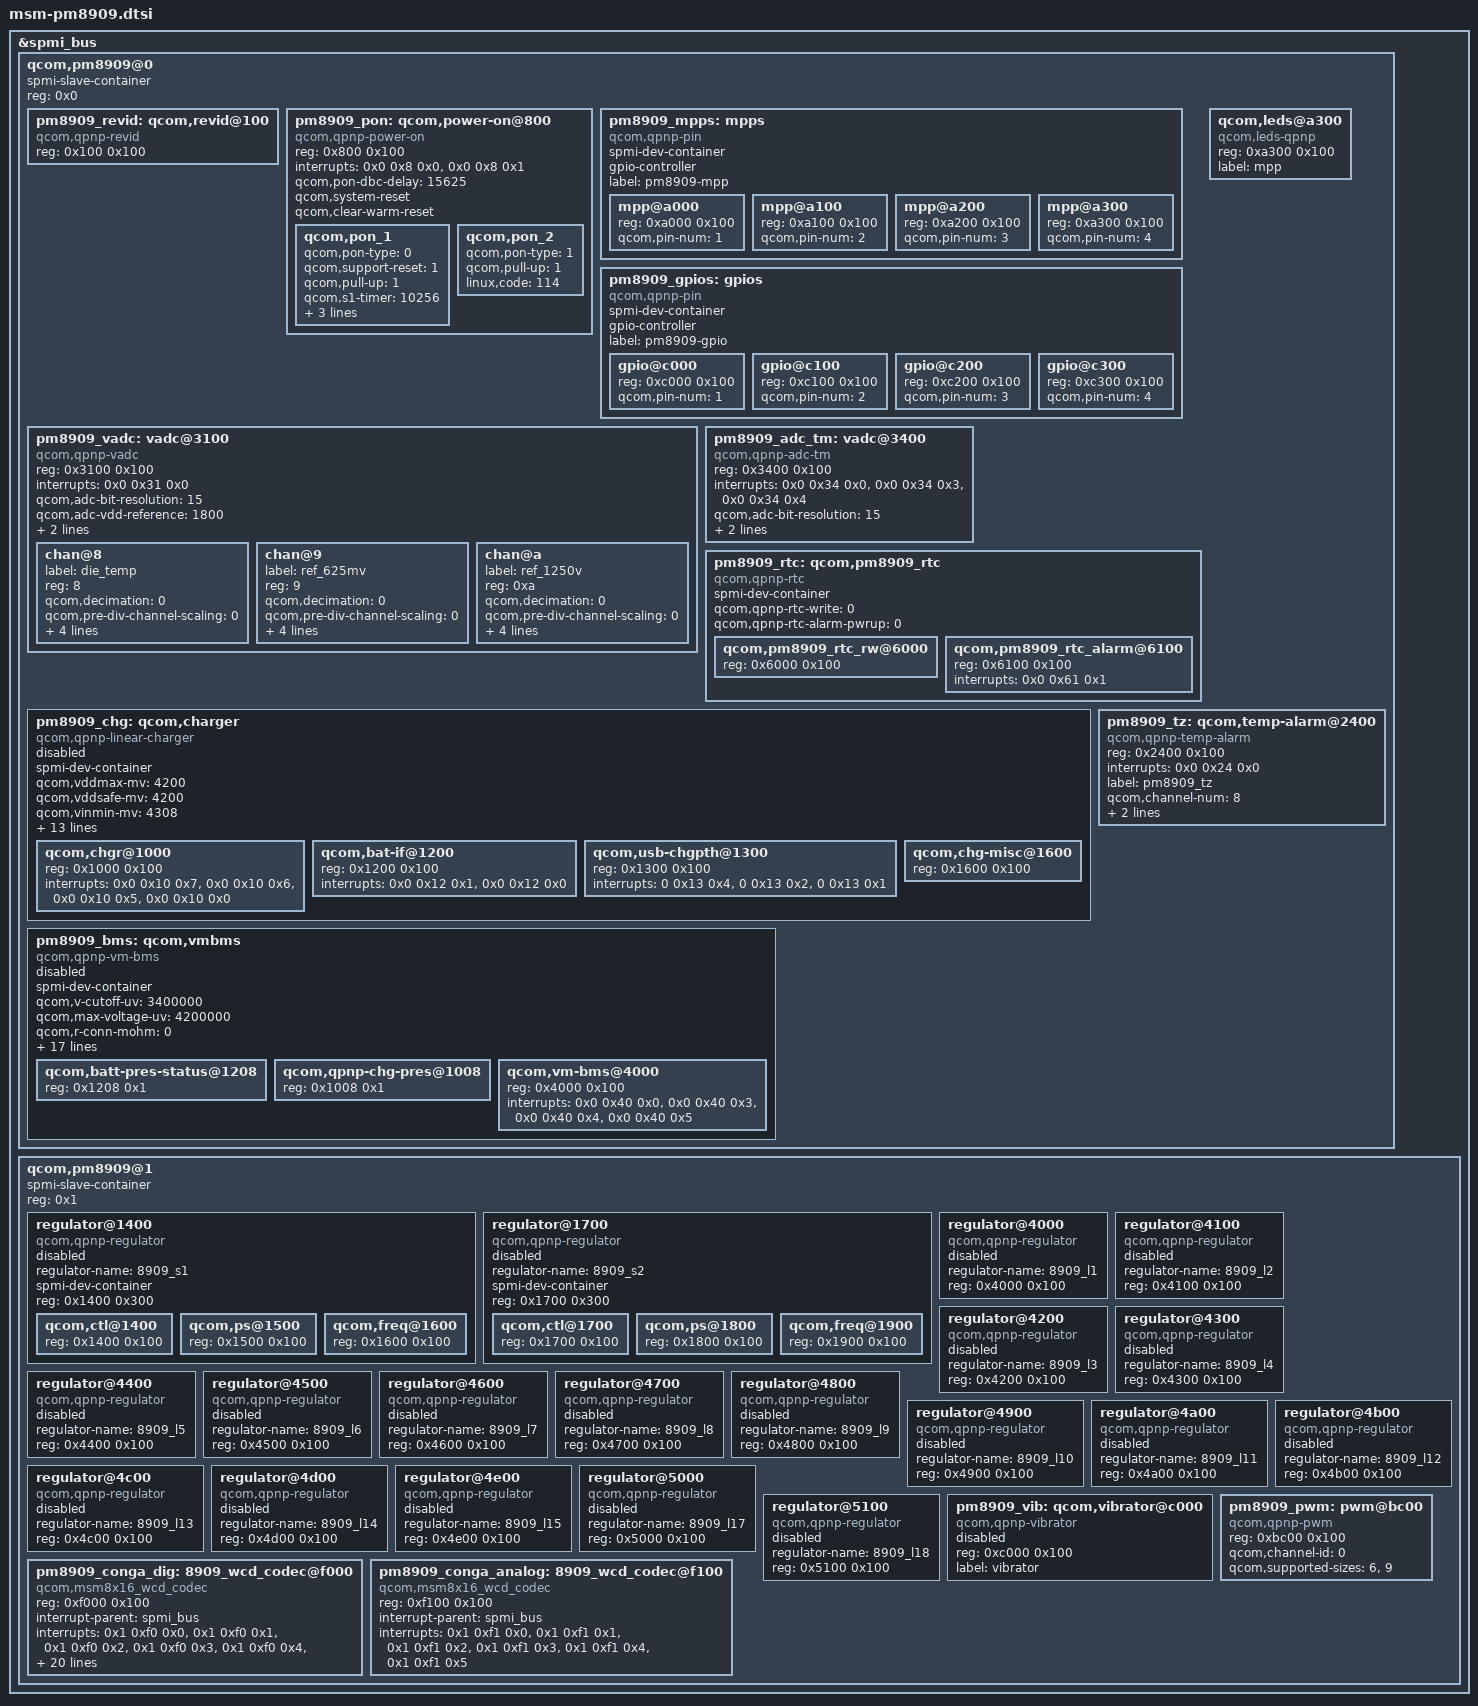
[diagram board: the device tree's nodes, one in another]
/* Copyright (c) 2014-2015, The Linux Foundation. All rights reserved.
 *
 * This program is free software; you can redistribute it and/or modify
 * it under the terms of the GNU General Public License version 2 and
 * only version 2 as published by the Free Software Foundation.
 *
 * This program is distributed in the hope that it will be useful,
 * but WITHOUT ANY WARRANTY; without even the implied warranty of
 * MERCHANTABILITY or FITNESS FOR A PARTICULAR PURPOSE.  See the
 * GNU General Public License for more details.
 */

&spmi_bus {

	qcom,pm8909@0 {
		spmi-slave-container;
		reg = <0x0>;
		#address-cells = <1>;
		#size-cells = <1>;

		pm8909_revid: qcom,revid@100 {
			compatible = "qcom,qpnp-revid";
			reg = <0x100 0x100>;
		};

		pm8909_pon: qcom,power-on@800 {
			compatible = "qcom,qpnp-power-on";
			reg = <0x800 0x100>;
			interrupts = <0x0 0x8 0x0>,
				     <0x0 0x8 0x1>;
			interrupt-names = "kpdpwr", "resin";
			qcom,pon-dbc-delay = <15625>;
			qcom,system-reset;
			qcom,clear-warm-reset;

			qcom,pon_1 {
				qcom,pon-type = <0>;
				qcom,support-reset = <1>;
				qcom,pull-up = <1>;
				qcom,s1-timer = <10256>;
				qcom,s2-timer = <2000>;
				qcom,s2-type = <1>;
				linux,code = <116>;
			};

			qcom,pon_2 {
				qcom,pon-type = <1>;
				qcom,pull-up = <1>;
				linux,code = <114>;
			};
		};

		pm8909_mpps: mpps {
			compatible = "qcom,qpnp-pin";
			spmi-dev-container;
			gpio-controller;
			#gpio-cells = <2>;
			#address-cells = <1>;
			#size-cells = <1>;
			label = "pm8909-mpp";

			mpp@a000 {
				reg = <0xa000 0x100>;
				qcom,pin-num = <1>;
			};

			mpp@a100 {
				reg = <0xa100 0x100>;
				qcom,pin-num = <2>;
			};

			mpp@a200 {
				reg = <0xa200 0x100>;
				qcom,pin-num = <3>;
			};

			mpp@a300 {
				reg = <0xa300 0x100>;
				qcom,pin-num = <4>;
			};
		};

		pm8909_gpios: gpios {
			compatible = "qcom,qpnp-pin";
			spmi-dev-container;
			gpio-controller;
			#gpio-cells = <2>;
			#address-cells = <1>;
			#size-cells = <1>;
			label = "pm8909-gpio";

			gpio@c000 {
				reg = <0xc000 0x100>;
				qcom,pin-num = <1>;
			};

			gpio@c100 {
				reg = <0xc100 0x100>;
				qcom,pin-num = <2>;
			};

			gpio@c200 {
				reg = <0xc200 0x100>;
				qcom,pin-num = <3>;
			};

			gpio@c300 {
				reg = <0xc300 0x100>;
				qcom,pin-num = <4>;
			};
		};

		pm8909_vadc: vadc@3100 {
			compatible = "qcom,qpnp-vadc";
			reg = <0x3100 0x100>;
			#address-cells = <1>;
			#size-cells = <0>;
			interrupts = <0x0 0x31 0x0>;
			interrupt-names = "eoc-int-en-set";
			qcom,adc-bit-resolution = <15>;
			qcom,adc-vdd-reference = <1800>;
			qcom,vadc-poll-eoc;
			qcom,pmic-revid = <&pm8909_revid>;

			chan@8 {
				label = "die_temp";
				reg = <8>;
				qcom,decimation = <0>;
				qcom,pre-div-channel-scaling = <0>;
				qcom,calibration-type = "absolute";
				qcom,scale-function = <3>;
				qcom,hw-settle-time = <0>;
				qcom,fast-avg-setup = <0>;
			};

			chan@9 {
				label = "ref_625mv";
				reg = <9>;
				qcom,decimation = <0>;
				qcom,pre-div-channel-scaling = <0>;
				qcom,calibration-type = "absolute";
				qcom,scale-function = <0>;
				qcom,hw-settle-time = <0>;
				qcom,fast-avg-setup = <0>;
			};

			chan@a {
				label = "ref_1250v";
				reg = <0xa>;
				qcom,decimation = <0>;
				qcom,pre-div-channel-scaling = <0>;
				qcom,calibration-type = "absolute";
				qcom,scale-function = <0>;
				qcom,hw-settle-time = <0>;
				qcom,fast-avg-setup = <0>;
			};
		};

		pm8909_adc_tm: vadc@3400 {
			compatible = "qcom,qpnp-adc-tm";
			reg = <0x3400 0x100>;
			#address-cells = <1>;
			#size-cells = <0>;
			interrupts =	<0x0 0x34 0x0>,
					<0x0 0x34 0x3>,
					<0x0 0x34 0x4>;
			interrupt-names =	"eoc-int-en-set",
						"high-thr-en-set",
						"low-thr-en-set";
			qcom,adc-bit-resolution = <15>;
			qcom,adc-vdd-reference = <1800>;
			qcom,adc_tm-vadc = <&pm8909_vadc>;
		};

		pm8909_rtc: qcom,pm8909_rtc {
			spmi-dev-container;
			compatible = "qcom,qpnp-rtc";
			#address-cells = <1>;
			#size-cells = <1>;
			qcom,qpnp-rtc-write = <0>;
			qcom,qpnp-rtc-alarm-pwrup = <0>;

			qcom,pm8909_rtc_rw@6000 {
				reg = <0x6000 0x100>;
			};
			qcom,pm8909_rtc_alarm@6100 {
				reg = <0x6100 0x100>;
				interrupts = <0x0 0x61 0x1>;
			};
		};

		qcom,leds@a300 {
			compatible = "qcom,leds-qpnp";
			reg = <0xa300 0x100>;
			label = "mpp";
		};

		pm8909_chg: qcom,charger {
			spmi-dev-container;
			compatible = "qcom,qpnp-linear-charger";
			#address-cells = <1>;
			#size-cells = <1>;

			qcom,vddmax-mv = <4200>;
			qcom,vddsafe-mv = <4200>;
			qcom,vinmin-mv = <4308>;
			qcom,ibatsafe-ma = <1440>;
			qcom,thermal-mitigation = <1440 720 630 0>;
			qcom,cool-bat-decidegc = <100>;
			qcom,warm-bat-decidegc = <450>;
			qcom,cool-bat-mv = <4100>;
			qcom,warm-bat-mv = <4100>;
			qcom,ibatmax-warm-ma = <360>;
			qcom,ibatmax-cool-ma = <360>;
			qcom,batt-hot-percentage = <25>;
			qcom,batt-cold-percentage = <80>;
			qcom,tchg-mins = <232>;
			qcom,chg-vadc = <&pm8909_vadc>;
			qcom,chg-adc_tm = <&pm8909_adc_tm>;

			status = "disabled";

			qcom,chgr@1000 {
				reg = <0x1000 0x100>;
				interrupts =	<0x0 0x10 0x7>,
						<0x0 0x10 0x6>,
						<0x0 0x10 0x5>,
						<0x0 0x10 0x0>;
				interrupt-names =	"chg-done",
							"chg-failed",
							"fast-chg-on",
							"vbat-det-lo";
			};

			qcom,bat-if@1200 {
				reg = <0x1200 0x100>;
				interrupts =	<0x0 0x12 0x1>,
						<0x0 0x12 0x0>;
				interrupt-names =	"bat-temp-ok",
							"batt-pres";
			};

			qcom,usb-chgpth@1300 {
				reg = <0x1300 0x100>;
				interrupts =	<0 0x13 0x4>,
						<0 0x13 0x2>,
						<0 0x13 0x1>;
				interrupt-names =	"usb-over-temp",
							"chg-gone",
							"usbin-valid";
			};

			qcom,chg-misc@1600 {
				reg = <0x1600 0x100>;
			};
		};

		pm8909_tz: qcom,temp-alarm@2400 {
			compatible = "qcom,qpnp-temp-alarm";
			reg = <0x2400 0x100>;
			interrupts = <0x0 0x24 0x0>;
			label = "pm8909_tz";
			qcom,channel-num = <8>;
			qcom,threshold-set = <0>;
			qcom,temp_alarm-vadc = <&pm8909_vadc>;
		};

		pm8909_bms: qcom,vmbms {
			spmi-dev-container;
			compatible = "qcom,qpnp-vm-bms";
			#address-cells = <1>;
			#size-cells = <1>;
			status = "disabled";

			qcom,v-cutoff-uv = <3400000>;
			qcom,max-voltage-uv = <4200000>;
			qcom,r-conn-mohm = <0>;
			qcom,shutdown-soc-valid-limit = <100>;
			qcom,low-soc-calculate-soc-threshold = <15>;
			qcom,low-voltage-calculate-soc-ms = <1000>;
			qcom,low-soc-calculate-soc-ms = <5000>;
			qcom,calculate-soc-ms = <20000>;
			qcom,volatge-soc-timeout-ms = <60000>;
			qcom,low-voltage-threshold = <3450000>;
			qcom,s3-ocv-tolerence-uv = <1200>;
			qcom,s2-fifo-length = <5>;
			qcom,low-soc-fifo-length = <2>;
			qcom,bms-vadc = <&pm8909_vadc>;
			qcom,bms-adc_tm = <&pm8909_adc_tm>;
			qcom,pmic-revid = <&pm8909_revid>;

			qcom,force-s3-on-suspend;
			qcom,force-s2-in-charging;
			qcom,report-charger-eoc;
			qcom,resume-soc = <99>;

			qcom,batt-pres-status@1208 {
				reg = <0x1208 0x1>;
			};

			qcom,qpnp-chg-pres@1008 {
				reg = <0x1008 0x1>;
			};

			qcom,vm-bms@4000 {
				reg = <0x4000 0x100>;
				interrupts =	<0x0 0x40 0x0>,
						<0x0 0x40 0x3>,
						<0x0 0x40 0x4>,
						<0x0 0x40 0x5>;

				interrupt-names = "leave_cv",
						  "ocv_thr",
						  "fifo_update_done",
						  "fsm_state_change";
			};
		};
	};

	qcom,pm8909@1 {
		spmi-slave-container;
		reg = <0x1>;
		#address-cells = <1>;
		#size-cells = <1>;

		regulator@1400 {
			compatible = "qcom,qpnp-regulator";
			regulator-name = "8909_s1";
			spmi-dev-container;
			#address-cells = <1>;
			#size-cells = <1>;
			reg = <0x1400 0x300>;
			status = "disabled";

			qcom,ctl@1400 {
				reg = <0x1400 0x100>;
			};
			qcom,ps@1500 {
				reg = <0x1500 0x100>;
			};
			qcom,freq@1600 {
				reg = <0x1600 0x100>;
			};
		};

		regulator@1700 {
			compatible = "qcom,qpnp-regulator";
			regulator-name = "8909_s2";
			spmi-dev-container;
			#address-cells = <1>;
			#size-cells = <1>;
			reg = <0x1700 0x300>;
			status = "disabled";

			qcom,ctl@1700 {
				reg = <0x1700 0x100>;
			};
			qcom,ps@1800 {
				reg = <0x1800 0x100>;
			};
			qcom,freq@1900 {
				reg = <0x1900 0x100>;
			};
		};

		regulator@4000 {
			compatible = "qcom,qpnp-regulator";
			regulator-name = "8909_l1";
			reg = <0x4000 0x100>;
			status = "disabled";
		};

		regulator@4100 {
			compatible = "qcom,qpnp-regulator";
			regulator-name = "8909_l2";
			reg = <0x4100 0x100>;
			status = "disabled";
		};

		regulator@4200 {
			compatible = "qcom,qpnp-regulator";
			regulator-name = "8909_l3";
			reg = <0x4200 0x100>;
			status = "disabled";
		};

		regulator@4300 {
			compatible = "qcom,qpnp-regulator";
			regulator-name = "8909_l4";
			reg = <0x4300 0x100>;
			status = "disabled";
		};

		regulator@4400 {
			compatible = "qcom,qpnp-regulator";
			regulator-name = "8909_l5";
			reg = <0x4400 0x100>;
			status = "disabled";
		};

		regulator@4500 {
			compatible = "qcom,qpnp-regulator";
			regulator-name = "8909_l6";
			reg = <0x4500 0x100>;
			status = "disabled";
		};

		regulator@4600 {
			compatible = "qcom,qpnp-regulator";
			regulator-name = "8909_l7";
			reg = <0x4600 0x100>;
			status = "disabled";
		};

		regulator@4700 {
			compatible = "qcom,qpnp-regulator";
			regulator-name = "8909_l8";
			reg = <0x4700 0x100>;
			status = "disabled";
		};

		regulator@4800 {
			compatible = "qcom,qpnp-regulator";
			regulator-name = "8909_l9";
			reg = <0x4800 0x100>;
			status = "disabled";
		};

		regulator@4900 {
			compatible = "qcom,qpnp-regulator";
			regulator-name = "8909_l10";
			reg = <0x4900 0x100>;
			status = "disabled";
		};

		regulator@4a00 {
			compatible = "qcom,qpnp-regulator";
			regulator-name = "8909_l11";
			reg = <0x4a00 0x100>;
			status = "disabled";
		};

		regulator@4b00 {
			compatible = "qcom,qpnp-regulator";
			regulator-name = "8909_l12";
			reg = <0x4b00 0x100>;
			status = "disabled";
		};

		regulator@4c00 {
			compatible = "qcom,qpnp-regulator";
			regulator-name = "8909_l13";
			reg = <0x4c00 0x100>;
			status = "disabled";
		};

		regulator@4d00 {
			compatible = "qcom,qpnp-regulator";
			regulator-name = "8909_l14";
			reg = <0x4d00 0x100>;
			status = "disabled";
		};

		regulator@4e00 {
			compatible = "qcom,qpnp-regulator";
			regulator-name = "8909_l15";
			reg = <0x4e00 0x100>;
			status = "disabled";
		};

		regulator@5000 {
			compatible = "qcom,qpnp-regulator";
			regulator-name = "8909_l17";
			reg = <0x5000 0x100>;
			status = "disabled";
		};

		regulator@5100 {
			compatible = "qcom,qpnp-regulator";
			regulator-name = "8909_l18";
			reg = <0x5100 0x100>;
			status = "disabled";
		};

		pm8909_vib: qcom,vibrator@c000 {
			compatible = "qcom,qpnp-vibrator";
			reg = <0xc000 0x100>;
			label = "vibrator";
			status = "disabled";
		};

		pm8909_conga_dig: 8909_wcd_codec@f000 {
			compatible = "qcom,msm8x16_wcd_codec";
			reg = <0xf000 0x100>;
			interrupt-parent = <&spmi_bus>;
			interrupts = <0x1 0xf0 0x0>,
				     <0x1 0xf0 0x1>,
				     <0x1 0xf0 0x2>,
				     <0x1 0xf0 0x3>,
				     <0x1 0xf0 0x4>,
				     <0x1 0xf0 0x5>,
				     <0x1 0xf0 0x6>,
				     <0x1 0xf0 0x7>;
			interrupt-names = "spk_cnp_int",
					  "spk_clip_int",
					  "spk_ocp_int",
					  "ins_rem_det1",
					  "but_rel_det",
					  "but_press_det",
					  "ins_rem_det",
					  "mbhc_int";

			cdc-vdda-cp-supply = <&pm8909_s2>;
			qcom,cdc-vdda-cp-voltage = <1800000 2200000>;
			qcom,cdc-vdda-cp-current = <500000>;

			cdc-vdda-h-supply = <&pm8909_l5>;
			qcom,cdc-vdda-h-voltage = <1800000 1800000>;
			qcom,cdc-vdda-h-current = <10000>;

			cdc-vdd-px-supply = <&pm8909_l5>;
			qcom,cdc-vdd-px-voltage = <1800000 1800000>;
			qcom,cdc-vdd-px-current = <5000>;

			cdc-vdd-pa-supply = <&pm8909_s2>;
			qcom,cdc-vdd-pa-voltage = <1800000 2200000>;
			qcom,cdc-vdd-pa-current = <260000>;

			cdc-vdd-mic-bias-supply = <&pm8909_l13>;
			qcom,cdc-vdd-mic-bias-voltage = <3075000 3075000>;
			qcom,cdc-vdd-mic-bias-current = <5000>;

			qcom,cdc-mclk-clk-rate = <9600000>;

			qcom,cdc-static-supplies = "cdc-vdda-h",
						   "cdc-vdd-px",
						   "cdc-vdd-pa",
						   "cdc-vdda-cp";

			qcom,cdc-on-demand-supplies = "cdc-vdd-mic-bias";
		};

		pm8909_conga_analog: 8909_wcd_codec@f100 {
			compatible = "qcom,msm8x16_wcd_codec";
			reg = <0xf100 0x100>;
			interrupt-parent = <&spmi_bus>;
			interrupts = <0x1 0xf1 0x0>,
				     <0x1 0xf1 0x1>,
				     <0x1 0xf1 0x2>,
				     <0x1 0xf1 0x3>,
				     <0x1 0xf1 0x4>,
				     <0x1 0xf1 0x5>;
			interrupt-names = "ear_ocp_int",
					  "hphr_ocp_int",
					  "hphl_ocp_det",
					  "ear_cnp_int",
					  "hphr_cnp_int",
					  "hphl_cnp_int";
		};

		pm8909_pwm: pwm@bc00 {
			compatible = "qcom,qpnp-pwm";
			reg = <0xbc00 0x100>;
			reg-names = "qpnp-lpg-channel-base";
			qcom,channel-id = <0>;
			qcom,supported-sizes = <6>, <9>;
			#pwm-cells = <2>;
		};
	};
};
